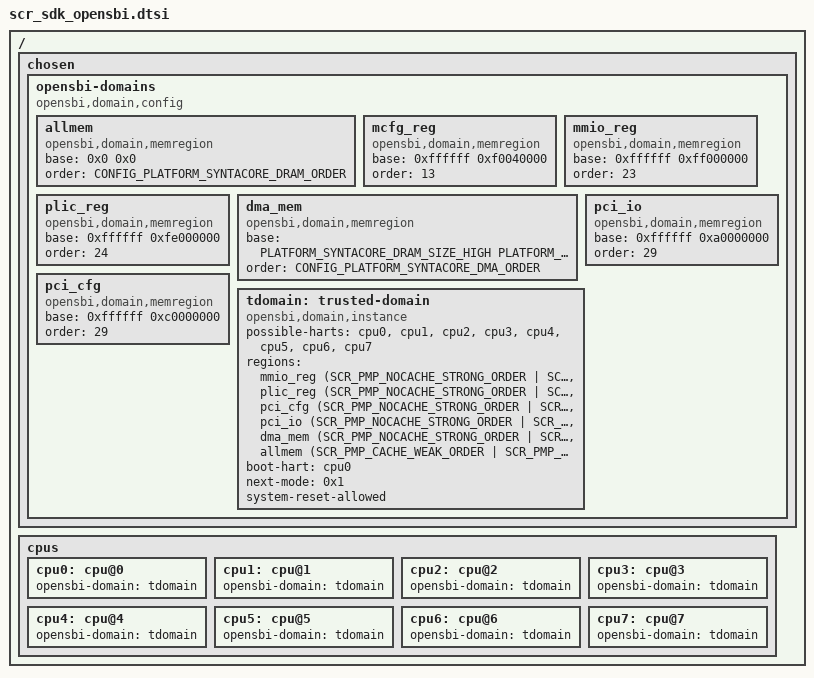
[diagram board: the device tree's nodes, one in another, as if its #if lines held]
/*
 * Copyright (C) 2022, Syntacore Ltd.
 *
 * Redistribution and use in source and binary forms, with or without
 * modification, are permitted provided that the following conditions are met:
 *     1. Redistributions of source code must retain the above copyright notice,
 *        this list of conditions and the following disclaimer.
 *     2. Redistributions in binary form must reproduce the above copyright
 *        notice, this list of conditions and the following disclaimer in the
 *        documentation and/or other materials provided with the distribution.
 *     3. Neither the name of the copyright holder nor the names of its
 *        contributors may be used to endorse or promote products derived from
 *        this software without specific prior written permission.
 *
 * THIS SOFTWARE IS PROVIDED BY THE COPYRIGHT HOLDERS AND CONTRIBUTORS "AS IS" AND
 * ANY EXPRESS OR IMPLIED WARRANTIES, INCLUDING, BUT NOT LIMITED TO, THE IMPLIED
 * WARRANTIES OF MERCHANTABILITY AND FITNESS FOR A PARTICULAR PURPOSE ARE
 * DISCLAIMED. IN NO EVENT SHALL THE COPYRIGHT HOLDER OR CONTRIBUTORS BE LIABLE
 * FOR ANY DIRECT, INDIRECT, INCIDENTAL, SPECIAL, EXEMPLARY, OR CONSEQUENTIAL
 * DAMAGES (INCLUDING, BUT NOT LIMITED TO, PROCUREMENT OF SUBSTITUTE GOODS OR
 * SERVICES; LOSS OF USE, DATA, OR PROFITS; OR BUSINESS INTERRUPTION) HOWEVER
 * CAUSED AND ON ANY THEORY OF LIABILITY, WHETHER IN CONTRACT, STRICT LIABILITY,
 * OR TORT (INCLUDING NEGLIGENCE OR OTHERWISE) ARISING IN ANY WAY OUT OF THE USE
 * OF THIS SOFTWARE, EVEN IF ADVISED OF THE POSSIBILITY OF SUCH DAMAGE.
 */

#include "scr_sdk_convert.h"
#ifdef CONFIG_PLATFORM_SYNTACORE_PMP
#include "../include/dt-bindings/scr_pmp.h"
#else
#include "../include/dt-bindings/scr_mpu.h"
#endif

/ {
	chosen {
		opensbi-domains {
			compatible = "opensbi,domain,config";

			allmem: allmem {
				compatible = "opensbi,domain,memregion";
				base = <0x0 0x0>;
				order = <CONFIG_PLATFORM_SYNTACORE_DRAM_ORDER>;
			};

			mcfg_reg: mcfg_reg {
				compatible = "opensbi,domain,memregion";
				base = <0xffffff 0xf0040000>;
				order = <13>;
			};

			mmio_reg: mmio_reg {
				compatible = "opensbi,domain,memregion";
				base = <0xffffff 0xff000000>;
				order = <23>;
			};

			plic_reg: plic_reg {
				compatible = "opensbi,domain,memregion";
				base = <0xffffff 0xfe000000>;
				order = <24>;
			};

			dma_mem: dma_mem {
				compatible = "opensbi,domain,memregion";
				base = <PLATFORM_SYNTACORE_DRAM_SIZE_HIGH PLATFORM_SYNTACORE_DRAM_SIZE_LOW>;
				order = <CONFIG_PLATFORM_SYNTACORE_DMA_ORDER>;
			};

			pci_io: pci_io {
				compatible = "opensbi,domain,memregion";
				base = <0xffffff 0xa0000000>;
				order = <29>;
			};

			pci_cfg: pci_cfg {
				compatible = "opensbi,domain,memregion";
				base = <0xffffff 0xc0000000>;
				order = <29>;
			};

			tdomain: trusted-domain {
				compatible = "opensbi,domain,instance";
				possible-harts = <
					&cpu0
#if CONFIG_PLATFORM_SYNTACORE_NR_CPUS > 1
					&cpu1
#endif
#if CONFIG_PLATFORM_SYNTACORE_NR_CPUS > 2
					&cpu2
#endif
#if CONFIG_PLATFORM_SYNTACORE_NR_CPUS > 3
					&cpu3
#endif
#if CONFIG_PLATFORM_SYNTACORE_NR_CPUS > 4
					&cpu4
#endif
#if CONFIG_PLATFORM_SYNTACORE_NR_CPUS > 5
					&cpu5
#endif
#if CONFIG_PLATFORM_SYNTACORE_NR_CPUS > 6
					&cpu6
#endif
#if CONFIG_PLATFORM_SYNTACORE_NR_CPUS > 7
					&cpu7
#endif
					>;
#ifdef CONFIG_PLATFORM_SYNTACORE_PMP
				regions =
					<&mmio_reg (SCR_PMP_NOCACHE_STRONG_ORDER | SCR_PMP_RW)>,
					<&plic_reg (SCR_PMP_NOCACHE_STRONG_ORDER | SCR_PMP_RW)>,
					<&pci_cfg  (SCR_PMP_NOCACHE_STRONG_ORDER | SCR_PMP_RW)>,
					<&pci_io   (SCR_PMP_NOCACHE_STRONG_ORDER | SCR_PMP_RW)>,
					<&dma_mem  (SCR_PMP_NOCACHE_STRONG_ORDER | SCR_PMP_RW)>,
					<&allmem   (SCR_PMP_CACHE_WEAK_ORDER | SCR_PMP_RWX)>;
#else
				regions =
					<&mcfg_reg (SCR_MPU_MMIO | SCR_MPU_NOCACHE_STRONG_ORDER | SCR_MPU_DEFINED_FLAGS | SCR_MPU_MMODE_RW)>,
					<&mmio_reg (SCR_MPU_NOCACHE_STRONG_ORDER | SCR_MPU_DEFINED_FLAGS | SCR_MPU_MMODE_RW | SCR_MPU_SMODE_RW)>,
					<&plic_reg (SCR_MPU_NOCACHE_STRONG_ORDER | SCR_MPU_DEFINED_FLAGS | SCR_MPU_MMODE_RW | SCR_MPU_SMODE_RW)>,
					<&pci_cfg  (SCR_MPU_NOCACHE_STRONG_ORDER | SCR_MPU_DEFINED_FLAGS | SCR_MPU_MMODE_RW | SCR_MPU_SMODE_RW)>,
					<&pci_io   (SCR_MPU_NOCACHE_STRONG_ORDER | SCR_MPU_DEFINED_FLAGS | SCR_MPU_MMODE_RW | SCR_MPU_SMODE_RW)>,
					<&dma_mem  (SCR_MPU_NOCACHE_STRONG_ORDER | SCR_MPU_DEFINED_FLAGS | SCR_MPU_MMODE_RW | SCR_MPU_SMODE_RW)>,
					<&allmem   (SCR_MPU_DEFINED_FLAGS | SCR_MPU_MODE_ALL)>;
#endif
				boot-hart = <&cpu0>;
				/* 0 = U, 1 = S, 3 = M */
				next-mode = <0x1>;
				system-reset-allowed;
			};
		};
	};

	cpus {
		cpu0: cpu@0 {
			opensbi-domain = <&tdomain>;
		};
#if CONFIG_PLATFORM_SYNTACORE_NR_CPUS > 1
		cpu1: cpu@1 {
			opensbi-domain = <&tdomain>;
		};
#endif
#if CONFIG_PLATFORM_SYNTACORE_NR_CPUS > 2
		cpu2: cpu@2 {
			opensbi-domain = <&tdomain>;
		};
#endif
#if CONFIG_PLATFORM_SYNTACORE_NR_CPUS > 3
		cpu3: cpu@3 {
			opensbi-domain = <&tdomain>;
		};
#endif
#if CONFIG_PLATFORM_SYNTACORE_NR_CPUS > 4
		cpu4: cpu@4 {
			opensbi-domain = <&tdomain>;
		};
#endif
#if CONFIG_PLATFORM_SYNTACORE_NR_CPUS > 5
		cpu5: cpu@5 {
			opensbi-domain = <&tdomain>;
		};
#endif
#if CONFIG_PLATFORM_SYNTACORE_NR_CPUS > 6
		cpu6: cpu@6 {
			opensbi-domain = <&tdomain>;
		};
#endif
#if CONFIG_PLATFORM_SYNTACORE_NR_CPUS > 7
		cpu7: cpu@7 {
			opensbi-domain = <&tdomain>;
		};
#endif
	};
};
